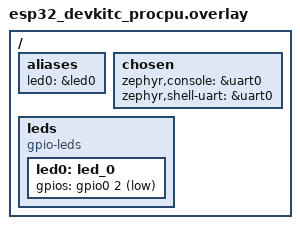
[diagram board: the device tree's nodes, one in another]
/ {
    aliases {
        led0 = &led0;
    };

    chosen {
        zephyr,console = &uart0;
        zephyr,shell-uart = &uart0;
    };

    leds {
        compatible = "gpio-leds";
        led0: led_0 {
            gpios = <&gpio0 2 GPIO_ACTIVE_LOW>;
        };
    };
};

